# nrf9220_application register map
Vendor: Nordic Semiconductor; Series: nRF92; File version: 1
CPU: CM33 r1p0, little endian, MPU, FPU, 3 interrupt priority bits, 480 interrupts, 4 SAU regions
Registers are 32-bit, read-write, reset 0x0 unless marked. A register's access mark holds for its fields unless they carry their own. Offsets are from the block's base; [hi:lo] are bit positions; lines under a group give offsets from that group; {n}, {i} and the like mark numbered series; 'fields as' and 'values as' point back to an identical list; <NAME> marks a mode.

## GLOBAL_STM_NS — System Trace Macrocell
Base 0xBF042000
0xC04 DMASTARTR wo — Starts a DMA transfer. A write of b1 when the DMA peripheral request interface is idle starts a DMA transfer. A write of b0 has no effect. A write of b1 when the DMA peripheral request interface is active has no effect.
  [0] START — Start a DMA transfer.
    0=NoEffect; 1=Start a DMA transfer
0xC08 DMASTOPR wo — Stops a DMA transfer. A write of b1 stops an active DMA transfer. A write of b0 has no effect. A write of b1 when the DMA peripheral request interface is idle has no effect.
  [0] STOP — Stop a DMA transfer.
    0=NoEffect; 1=Stop a DMA transfer
0xC0C DMASTATR ro — Indicates whether a DMA transfer is in progress.
  [0] STATUS — Status of the DMA peripheral request interface.
    0=Idle (Interface is idle.); 1=Active (Interface is active.)
0xC10 DMACTLR — Controls the DMA transfer request mechanism.
  [3:2] SENS — Determines the sensitivity of the DMA request to the current buffer level in the STM
    0=LT25 (Buffer is <25 percent full.); 1=LT50 (Buffer is <50 percent full.); 2=LT75 (Buffer is <75 percent full.); 3=LT100 (Buffer is <100 percent full.)
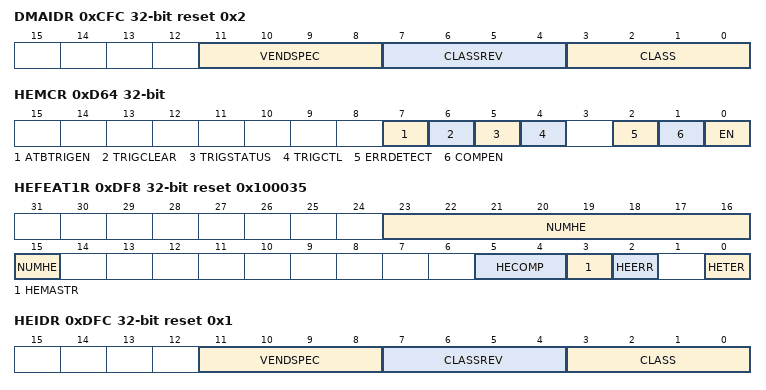
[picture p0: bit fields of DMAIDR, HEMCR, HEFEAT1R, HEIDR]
0xCFC DMAIDR ro reset 0x2 — Indicates the features of the DMA controls in the STM.
  [11:8] VENDSPEC — The VENDSPEC field identifies any vendor specific modifications or mappings
  [7:4] CLASSREV — The CLASSREV field identifies the revision of the programmers model
  [3:0] CLASS — The CLASS field identifies the programmers model
    2=DMA control programmers model
0xD00 HEER — Enables hardware events to generate trace.
  [31:0] HEE — Hardware event enable, with one bit per hardware event. A bit value of b0 disables and b1 enables the corresponding hardware event. Bit 0 applies to the lowest-numbered event. The reset value of each bit is UNKNOWN.
0xD20 HETER — Enables trigger generation on hardware events.
  [31:0] HETE — Bit mask to enable trigger generation from the hardware events, with one bit per hardware event. A bit value of b0 disables and b1 enables trigger generation. The reset value of each bit is UNKNOWN.
0xD64 HEMCR — Controls the primary functions of the hardware event tracing.
  [7] ATBTRIGEN — ATB trigger enable on events being monitored using the HETER. When set, this bit enables the STM to use the ATID value of 0x7D.
    0=Disabled (ATB trigger generation is disabled.); 1=Enabled (ATB trigger generation is enabled.)
  [6] TRIGCLEAR wo — When TRIGCTL indicates single-shot mode, this bit is used to clear TRIGSTATUS. Writing a b1 to this bit when in multi-shot mode is Unpredictable.
    0=NoEffect; 1=Clears TRIGSTATUS if TRIGSTATUS is b1
  [5] TRIGSTATUS ro — When TRIGCTL indicates single-shot mode, this indicates whether the single trigger has occurred. In multi-shot mode this bit is always UNKNOWN.
    0=NotOccurred (Trigger has not occurred.); 1=Occurred (Trigger has occurred.)
  [4] TRIGCTL — Trigger control.
    0=MultiShot (Triggers are multi-shot.); 1=SingleShot (Triggers are single-shot.)
  [2] ERRDETECT — Enable error detection on the hardware event tracing. If an event cannot be traced, this bit enables indication of the lost information.
    0=Disabled (Error detection is disabled.); 1=Enabled (Error detection is enabled.)
  [1] COMPEN — Enable leading zero suppression of hardware event data values in the trace stream.
    0=Disabled (Leading zero suppression is disabled.); 1=Enabled (Leading zero suppression is enabled.)
  [0] EN — Enable hardware event tracing. To enable hardware event tracing, TCSR.EN must also be b1.
    0=Disabled (Hardware event tracing is disabled.); 1=Enabled (Hardware event tracing is enabled.)
0xDF4 HEMASTR ro reset 0x80 — Indicates the STPv2 master number of hardware event trace. This number is the master number presented in STPv2.
  [15:0] MASTER — The STPv2 master number that hardware event traces should be associated with.
0xDF8 HEFEAT1R ro reset 0x100035 — Indicates the features of the STM.
  [23:15] NUMHE — The number of hardware events supported by the STM
  [5:4] HECOMP — Data compression on hardware event tracing support
    0=NotDefinedHere (Data compression support is not defined here. Use the part number of the device to determine if data compression is supported.); 1=NotSupported (No data compression supported.); 2=AlwaysEnabled (Data compression always enabled.); 3=Programmable (Data compression support is programmable. STMHEMCR.COMPEN is implemented.)
  [3] HEMASTR — STMHEMASTR support
    0=ReadOnly (STMHEMASTR is read-only.); 1=ReadWrite (STMHEMASTR is read-write.)
  [2] HEERR — Hardware event error detection support
    0=NotImplemented (The feature is not implemented.); 1=Implemented (The feature is implemented.)
  [0] HETER — STMHETER support
    values as HEERR
0xDFC HEIDR ro reset 0x1 — Indicates the features of hardware event tracing in the STM.
  [11:8] VENDSPEC — The VENDSPEC field identifies any vendor specific modifications or mappings
  [7:4] CLASSREV — The CLASSREV field identifies the revision of the programmers model
  [3:0] CLASS — The CLASS field identifies the programmers model
    1=Hardware Event Control programmers model
0xE00 SPER — Enables the stimulus port registers to generate trace. This register defines one bit per stimulus port. This register is used in conjunction with the SPSCR.
  [31:0] SPE — Stimulus port enable, with one bit per stimulus port. A bit value of b0 disables and b1 enables the corresponding stimulus port. The reset value of each bit is b0.
0xE20 SPTER — Enables trigger generation on writes to enabled stimulus port registers.
  [31:0] SPTE — Bit mask to enable trigger generation from the stimulus port registers, with one bit per stimulus port register. A bit value of b0 disables and b1 enables trigger generation. The reset value of each bit is b0.
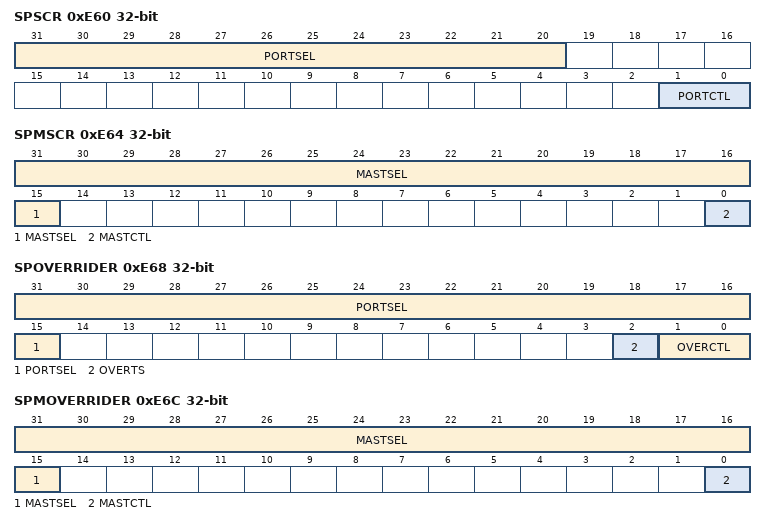
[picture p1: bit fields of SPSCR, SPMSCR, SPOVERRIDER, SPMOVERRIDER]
0xE60 SPSCR — Enables a debugger to program which stimulus ports the SPER and SPTER apply to.
  [31:20] PORTSEL — Port Selection. This field defines which group of 32 stimulus ports the SPTER and SPER apply to. The bottom N bits which are 0 define a mask, a 1 in bit N+1 demarks the mask from the port selection, and the remaining bits select the groups. The effective size of this field is defined by the number of implemented stimulus ports. The reset value is UNKNOWN.
  [1:0] PORTCTL — This defines how the port selection is applied. The reset value is b00.
    0=NotUsed (Port selection not used. SPER and SPTER apply equally to every group of 32 stimulus ports and PORTSEL is ignored.); 1=TriggerEnableOnly (Port selection applies only to the SPTER.); 3=EnableAndTriggerEnable (Port selection applies to both the SPER and SPTER.)
0xE64 SPMSCR — Enables a debugger to program which masters the SPSCR applies to.
  [31:15] MASTSEL — Master Selection. This field defines which master the SPSCR applies to. The bottom N bits which are 0 define a mask, a 1 in bit N+1 demarks the mask from the master selection, and the remaining bits select the master. The effective size of this field is defined by the number of implemented masters. The reset value is UNKNOWN.
  [0] MASTCTL — This bit defines how the master is applied. The reset value is b0.
    0=NotUsed (Master selection not used. The port selection used by the SPSCR applies equally to all masters and MASTSEL is ignored.); 1=Used (Master selection applies to the SPSCR.)
0xE68 SPOVERRIDER — Enables a debugger to override various features of the STM. This register is used in conjunction with SPMOVERRIDER.
  [31:15] PORTSEL — Port selection. This field defines which stimulus ports the override controls apply to. The bottom N bits which are 0 define a mask, a 1 in bit N+1 delimits the mask from the port selection, and the remaining bits select the ports. The effective size of this field is defined by the number of implemented stimulus ports. The reset value is UNKNOWN.
  [2] OVERTS — Timestamping override. This override requests all stimulus port writes that cause trace to be traced with a timestamp where possible. As with normal operation, this does not ensure all packets are generated with timestamps. This field is independent of OVERCTL, PORTSEL and SPMOVERRIDER. The reset value is b0.
    0=Disabled (Override not enabled.); 1=Enabled (Override enabled.)
  [1:0] OVERCTL — This defines how the port selection is applied. The reset value is b00.
    0=Disabled (Override controls disabled.); 1=Guaranteed (Ports selected by PORTSEL always behave as guaranteed transactions.); 2=InvariantTiming (Ports selected by PORTSEL always behave as invariant timing transactions.)
0xE6C SPMOVERRIDER — Enables a debugger to select which masters the SPOVERRIDER applies to.
  [31:15] MASTSEL — Master selection. This field defines which master the override controls apply to. The effective size of this field is defined by the number of implemented masters. The reset value is UNKNOWN.
  [0] MASTCTL — This bit defines how the master selection is applied. The reset value is b0.
    0=NotUsed (Master selection not enabled. SPOVERRIDER applies equally to all masters and MASTSEL is ignored.); 1=Used (Master selection enabled. SPOVERRIDER applies to the masters selected by MASTSEL.)
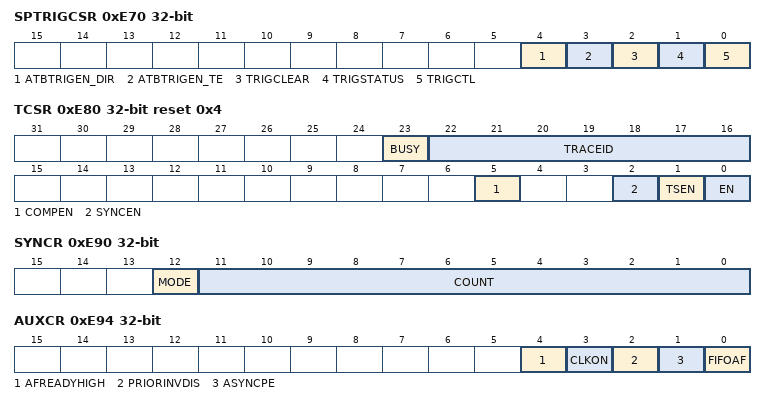
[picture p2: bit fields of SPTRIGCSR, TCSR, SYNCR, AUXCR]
0xE70 SPTRIGCSR — Controls the STM triggers caused by the SPTER.
  [4] ATBTRIGEN_DIR — ATB trigger enable on direct writes to TRIG locations in an extended stimulus port. When set, this bit enables the STM to use the ATID value of 0x7D when software writes to the TRIG locations. The reset value is b0.
    values as HEMCR.ATBTRIGEN
  [3] ATBTRIGEN_TE — ATB trigger enable on writes to stimulus ports being monitored using the SPTER. When set, this bit enables the STM to use the ATID value of 0x7D when software writes to an enabled stimulus port. The reset value is b0.
    values as HEMCR.ATBTRIGEN
  [2] TRIGCLEAR wo — When TRIGCTL indicates single-shot mode, this bit is used to clear TRIGSTATUS. Writing a b1 to this bit when in multi-shot mode is Unpredictable.
    0=NoEffect; 1=Clears TRIGSTATUS if TRIGSTATUS is b1
  [1] TRIGSTATUS ro — When TRIGCTL indicates single-shot mode, this bit indicates whether the single trigger has occurred. In multi-shot mode this bit is always UNK/SBZP.
    values as HEMCR.TRIGSTATUS
  [0] TRIGCTL — Trigger control. The reset value is b0.
    values as HEMCR.TRIGCTL
0xE80 TCSR reset 0x4 — Controls the STM settings.
  [23] BUSY — STM is busy, for example the STM trace FIFO is not empty.
    0=Ready (STM is not busy.); 1=Busy (STM is busy.)
  [22:16] TRACEID — ATB Trace ID. Setting this value to all zeroes might result in Unpredictable tracing.
  [5] COMPEN — Compression Enable for Stimulus Ports.
    0=Disabled (Compression disabled, data transfers are transmitted at the size of the transaction.); 1=Enabled (Compression enabled, data transfers are compressed to save bandwidth.)
  [2] SYNCEN — STMSYNCR is implemented so this value is Read As One.
    0=Disabled (The STM Sync feature is disabled.); 1=Enabled (The STM Sync feature is enabled.)
  [1] TSEN — Enable or disable timestamp bundling.
    0=Disabled (Time stamps are disabled. Requests for timestamp generation are ignored, and stimulus port writes selecting timestamping are treated as if it were not selected.); 1=Enabled (Time stamps are enabled. If stimulus writes select timestamping, a timestamp is output according to STPv2.)
  [0] EN — Global STM enable
    0=Disabled (The STM is disabled.); 1=Enabled (The STM is enabled.)
0xE84 TSSTIMR wo — Forces the next packet caused by a stimulus port write to have a timestamp output.
  [0] FORCETS — Force timestamp stimulus.
    0=Ignored (Writes with this bit b0 are ignored.); 1=Force (Requests the next stimulus port write which causes trace to be upgraded to have a timestamp.)
0xE8C TSFREQR — Indicates the frequency of the timestamp counter. The unit of measurement is increments per second.
  [31:0] FREQ — The timestamp frequency in Hz. A value of zero indicates the timestamp frequency is not known. The reset value is implementation defined.
0xE90 SYNCR — Controls the interval between synchronization packets, in terms of the number of bytes of trace generated. This register only provides a hint of the desired synchronization frequency, because implementations are permitted to be inaccurate. Writing a value of 0x00000000 disables the synchronization counter.
  [12] MODE — Mode control. The reset value is b0.
    0=Linear (COUNT[11:0] defines a value N. Synchronization period is N bytes.); 1=PowerOfTwo (COUNT[11:7] defines a value N. Synchronization period is 2N bytes. N must be in the range 12 to 27 inclusive and other values are Unpredictable.)
  [11:0] COUNT — Counter value for the number of bytes between synchronization packets. Reads return the value of this register. The reset value is implementation defined.
0xE94 AUXCR — Used for implementation defined STM controls.
  [4] AFREADYHIGH — Provides override control for the AFREADY output
    0=Disabled (No override, AFREADY is controlled by the state of STM.); 1=Enabled (Override, AFREADY is driven HIGH.)
  [3] CLKON — Provides override control for architectural clock gate enable.
    0=Disabled (No override, clock gate is controlled by the state of STM.); 1=Enabled (Override, clock is enabled.)
  [2] PRIORINVDIS — Controls arbitration between AXI and HW during flush.
    0=Priority inversion, when AXI flush is finished, HW gets priority until HW flush is done; 1=AxiAlwaysFirst (Priority inversion disabled, AXI always has priority over HW.)
  [1] ASYNCPE — Is ASYNC priority higher than trace?
    0=Lower (ASYNC priority is always lower than trace.); 1=Escalate (ASYNC priority escalates on second synchronization request.)
  [0] FIFOAF — FIFO Auto-flush.
    0=Disabled (Auto-flush is disabled.); 1=Enabled (Auto-flush is enabled. The STM automatically drains all data it has even if the ATB interface is not fully utilized.)
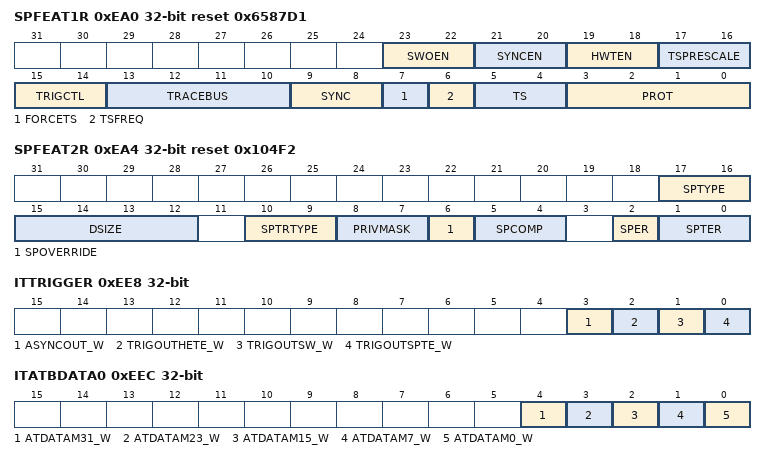
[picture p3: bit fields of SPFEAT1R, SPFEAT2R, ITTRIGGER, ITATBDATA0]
0xEA0 SPFEAT1R ro reset 0x6587D1 — Indicates the features of the STM.
  [23:22] SWOEN — STMTCSR.SWOEN support
    1=NotImplemented (STMTCSR.SWOEN not implemented)
  [21:20] SYNCEN — STMTCSR.SYNCEN support
    2=ReadAsOne (STMTCSR.SYNCEN implemented but always reads as b1)
  [19:18] HWTEN — STMTCSR.HWTEN support
    1=NotImplemented (STMTCSR.HWTEN is not implemented)
  [17:16] TSPRESCALE — Timestamp prescale support
    1=NotImplemented (Timestamp prescale is not implemented.); 2=Implemented (Timestamp prescale is implemented.)
  [15:14] TRIGCTL — Trigger control support.
    2=Multi-shot and single-shot triggers supported. STMSPTRIGCSR implemented.
  [13:10] TRACEBUS — Trace bus support.
    1=AtbPlusTrigger (CoreSight ATB plus ATB trigger support implemented. STMTCSR.TRACEID and STMSPTRIGCSR.ATBTRIGEN implemented.)
  [9:8] SYNC — STMSYNCR support.
    3=ImplementedWithMode (STMSYNCR implemented with MODE control.)
  [7] FORCETS — Timestamp force configuration.
    0=NotImplemented (STMTSSTIMR bit 0 is read-only.); 1=Implemented (STMTSSTIMR bit 0 is read-write.)
  [6] TSFREQ — Timestamp frequency indication configuration.
    0=NotImplemented (STMTSFREQR is read-only.); 1=Implemented (STMTSFREQR is read-write.)
  [5:4] TS — Timestamp support.
    1=Absolute timestamps implemented
  [3:0] PROT — Indicates the implemented STM protocol.
    1=STPV2 (STM implements the STPV2 protocol.)
0xEA4 SPFEAT2R ro reset 0x104F2 — Indicates the features of the STM.
  [17:16] SPTYPE — Stimulus port type support
    1=Only extended stimulus ports are implemented
  [15:12] DSIZE — Fundamental data size.
    0=Bits32 (32-bit data.)
  [10:9] SPTRTYPE — Stimulus port transaction type support.
    2=InvariantAndGuaranteed (Both invariant timing and guaranteed transactions are supported.)
  [8:7] PRIVMASK — STMPRIVMASKR support.
    1=NotImplemented (STMPRIVMASKR is not implemented.)
  [6] SPOVERRIDE — STMSPOVERRIDER and STMSPMOVERRIDER support.
    0=NotImplemented (STMSPOVERRIDER and STMSPMOVERRIDER is not implemented.); 1=Implemented (STMSPOVERRIDER and STMSPMOVERRIDER is implemented.)
  [5:4] SPCOMP — Data compression on stimulus ports support.
    3=Programmable (Data compression support is programmable. STMTCSR.COMPEN is implemented.)
  [2] SPER — STMSPER presence.
    0=Implemented (STMSPER is implemented.); 1=NotImplemented (STMSPER is not implemented.)
  [1:0] SPTER — STMSPTER support.
    2=Implemented (STMSPTER is implemented.)
0xEA8 SPFEAT3R ro reset 0x7F — Indicates the features of the STM.
  [6:0] NUMMAST — The number of stimulus ports masters implemented, minus 1.
    127=Masters128 (128 masters are implemented.)
0xEE8 ITTRIGGER wo — Integration Test for Cross-Trigger Outputs Register.
  [all] fields
    0=Low (Drive logic 0 on output.); 1=High (Drive logic 1 on output.)
  [3] ASYNCOUT_W — Sets the value of the ASYNCOUT output in integration mode.
  [2] TRIGOUTHETE_W — Sets the value of the TRIGOUTHETE output in integration mode.
  [1] TRIGOUTSW_W — Sets the value of the TRIGOUTSW output in integration mode.
  [0] TRIGOUTSPTE_W — Sets the value of the TRIGOUTSPTE output in integration mode.
0xEEC ITATBDATA0 wo — Controls the value of the ATDATAM output in integration mode.
  [all] fields
    values as the fields of ITTRIGGER
  [4] ATDATAM31_W — Sets the value of the ATDATAM[31].
  [3] ATDATAM23_W — Sets the value of the ATDATAM[23].
  [2] ATDATAM15_W — Sets the value of the ATDATAM[15].
  [1] ATDATAM7_W — Sets the value of the ATDATAM[7] output.
  [0] ATDATAM0_W — Sets the value of the ATDATAM[0].
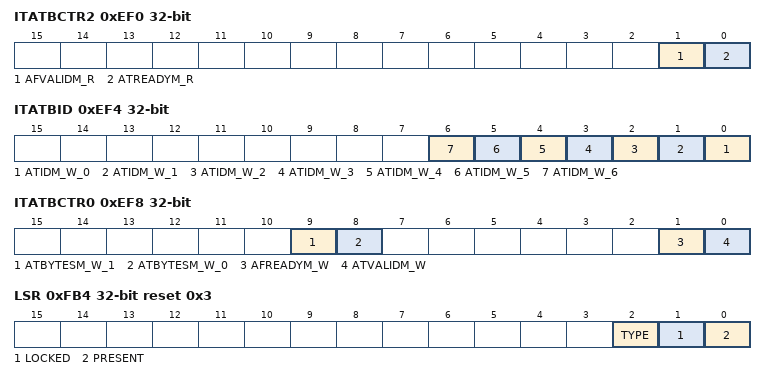
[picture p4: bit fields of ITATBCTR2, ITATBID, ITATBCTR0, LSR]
0xEF0 ITATBCTR2 ro — Returns the value of the ATREADYM and AFVALIDM inputs in integration mode.
  [1] AFVALIDM_R — Reads the value of the AFVALIDM input.
    0=Low (Pin is at logic 0.); 1=High (Pin is at logic 1.)
  [0] ATREADYM_R — Reads the value of the ATREADYM input.
    0=Low (Pin is at logic 0.); 1=High (Pin is at logic 1.)
0xEF4 ITATBID wo — Controls the value of the ATIDM output in integration mode.
  [all] fields
    values as the fields of ITTRIGGER
  [n] ATIDM_W_{n} (n=0..6) — Sets the value of pin {n} of the ATIDM output.
0xEF8 ITATBCTR0 wo — Controls the value of the ATVALIDM, AFREADYM, and ATBYTESM outputs in integration mode.
  [all] fields
    values as the fields of ITTRIGGER
  [9] ATBYTESM_W_1 — Sets the value of pin 1 of the ATBYTESM output.
  [8] ATBYTESM_W_0 — Sets the value of pin 0 of the ATBYTESM output.
  [1] AFREADYM_W — Sets the value of the AFREADYM output.
  [0] ATVALIDM_W — Sets the value of the ATVALIDM output.
0xF00 ITCTRL — Used to enable topology detection. This register enables the component to switch from a functional mode, the default behavior, to integration mode where the inputs and outputs of the component can be directly controlled for integration testing and topology solving.
  [0] INTEGRATIONMODE — Enables the component to switch from functional mode to integration mode and back. If no integration functionality is implemented, this register must read as zero.
    0=Disabled (Integration mode is disabled.); 1=Enabled (Integration mode is Enabled.)
0xFA0 CLAIMSET reset 0xF — On writes this register sets bits of the claim tag. On reads it indicates the number of claim tag bits implemented.
  [3:0] CLAIMSET — On reads, each bit reads as b1 if the claim tag bit is implemented. Four claim tag bits are implemented, so this register reads as 0xF. On writes, a b1 in a bit position causes the corresponding claim tag bit to be set.
0xFA4 CLAIMCLR — On writes this register clears bits of the claim tag. On reads it indicates the current status of the claim tag.
  [3:0] CLAIMCLR — On reads, each bit reads as one if the claim tag bit is set. On writes, a b1 in a bit position causes the corresponding claim tag bit to be cleared. On a reset the claim tags are reset to b0.
0xFB0 LAR wo — This is used to enable write access to device registers.
  [31:0] ACCESS — A write of 0xC5ACCE55 enables further write access to this device. Any other write removes write access.
    0xC5ACCE55=Unlock register interface
0xFB4 LSR ro reset 0x3 — This indicates the status of the lock control mechanism. This lock prevents accidental writes by code under debug. Accesses to the extended stimulus port registers are not affected by the lock mechanism. This register must always be present although there might not be any lock access control mechanism. The lock mechanism, where present and locked, must block write accesses to any control register, except the Lock Access Register. For most components this covers all registers except for the Lock Access Register.
  [2] TYPE — Indicates if the Lock Access Register is implemented as 8-bit or 32-bit.
    0=Bits32 (This component implements a 32-bit Lock Access Register.); 1=Bits8 (This component implements an 8-bit Lock Access Register.)
  [1] LOCKED — Returns the current status of the Lock.
    0=UnLocked (Write access is allowed to this device.); 1=Locked (Write access to the component is blocked. All writes to control registers are ignored. Reads are permitted.)
  [0] PRESENT — Indicates that a lock control mechanism exists for this device.
    0=NotImplemented (No lock control mechanism exists, writes to the Lock Access Register are ignored.); 1=Implemented (Lock control mechanism is present.)
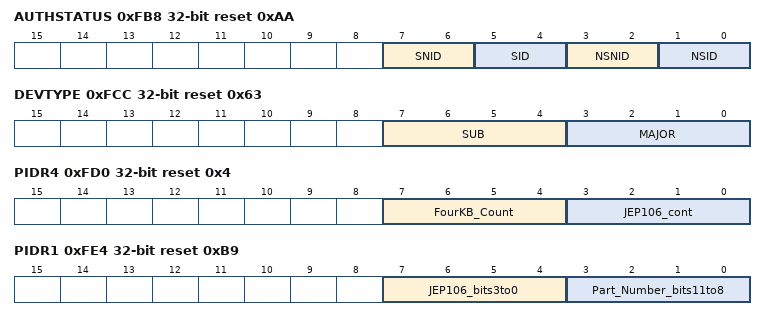
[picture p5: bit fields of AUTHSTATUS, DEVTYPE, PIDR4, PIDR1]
0xFB8 AUTHSTATUS ro reset 0xAA — Indicates the current level of tracing permitted by the system
  [all] fields
    2=Disabled (Functionality disabled.); 3=Enabled (Functionality enabled.)
  [7:6] SNID — Indicates the security level for secure non-invasive debug.
  [5:4] SID — Indicates the security level for secure invasive debug.
  [3:2] NSNID — Indicates the security level for non-secure non-invasive debug.
  [1:0] NSID — Indicates the security level for non-secure invasive debug.
0xFC8 DEVID ro reset 0x10000 — Indicates the capabilities of the STM.
  [16:0] NUMSP — This value indicates the number of stimulus ports implemented.
    0x10000=Max (Maximum 65,536 stimulus ports can be implemented.)
0xFCC DEVTYPE ro reset 0x63 — Provides a debugger with information about the component when the Part Number field is not recognized. The debugger can then report this information.
  [7:4] SUB — The sub-type of the component
    6=StimulusTrace (Peripheral is a stimulus trace source.)
  [3:0] MAJOR — The main type of the component
    3=TraceSource (Peripheral is a trace source.)
0xFD0 PIDR4 ro reset 0x4 — Coresight peripheral identification register. Contains part of the designer identity and the memory footprint indicator.
  [7:4] FourKB_Count — This is a 4-bit value that indicates the total contiguous size of the memory window used by this component in powers of 2 from the standard 4KB. If a component only requires the standard 4KB, this must read as 0x0, 4KB only. For 8KB set to 0x1, for 16KB set to 0x2, for 32KB set to 0x3, and so on.
    0=Size4KB (Indicates that the device only occupies 4KB of memory.)
  [3:0] JEP106_cont — JEDEC continuation code indicating the designer of the component, together with the identity code.
    4=Arm (Indicates that ARM's JEDEC identity code is on the 5th bank.)
0xFE0 PIDR0 ro reset 0x62 — Coresight peripheral identification register. Contains part of the designer specific part number.
  [7:0] Part_Number_bits7to0 — Bits [7:0] of the component part number. This is selected by the designer of the component.
    98=PartNumberLow (Lowest 8 bits of the Part Number, 0x962.)
0xFE4 PIDR1 ro reset 0xB9 — Coresight peripheral identification register. Contains part of the designer specific part number and part of the designer identity.
  [7:4] JEP106_bits3to0 — Bits [3:0] of the JEDEC identity code indicating the designer of the component, together with the continuation code.
    11=JEP106IdentityLow (Lowest 4 bits of the JEP106 Identity Code.)
  [3:0] Part_Number_bits11to8 — Bits [11:8] of the component part number. This is selected by the designer of the component.
    9=PartNumberHigh (Upper 4 bits of the Part Number, 0x962.)
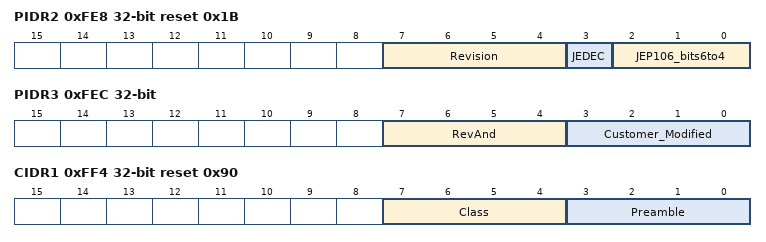
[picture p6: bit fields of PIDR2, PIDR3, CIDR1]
0xFE8 PIDR2 ro reset 0x1B — Coresight peripheral identification register. Contains part of the designer identity and the product revision.
  [7:4] Revision — The Revision field is an incremental value starting at 0x0 for the first design of this component. This only increases by 1 for both major and minor revisions and is used as a look-up to establish the exact major and minor revision.
    1=R0P1 (This device is at r0p1.)
  [3] JEDEC — Always set. Indicates that a JEDEC assigned value is used.
    1=JedecAssigned (The designer ID is specified by JEDEC (http://www.jedec.org).)
  [2:0] JEP106_bits6to4 — Bits [6:4] of the JEDEC identity code indicating the designer of the component, together with the continuation code.
    3=JEP106IdentityHigh (Upper 3 bits of the JEP106 Identity Code.)
0xFEC PIDR3 ro — Coresight peripheral identification register. Contains the RevAnd and Customer Modified fields.
  [7:4] RevAnd — This field indicates minor errata fixes specific to this design, for example metal fixes after implementation. In most cases this field is zero.
    0=NoMetalFixes (Indicates that there have been no metal fixes to this component.)
  [3:0] Customer_Modified — Where the component is reusable IP, this value indicates if the customer has modified the behavior of the component. In most cases this field is zero.
    0=NoModifications (Indicates that there have been no modifications made.)
0xFF0 CIDR0 ro reset 0xD — Coresight component identification register, that indicates that the identification registers are present.
  [7:0] Preamble — Contains bits [24:31] of the component identification.
    13=IdentificationValue
0xFF4 CIDR1 ro reset 0x90 — Coresight component identification register, that indicates that the identification registers are present. This register also indicates the component class.
  [7:4] Class — Class of the component, for example, ROM table or CoreSight component.
    9=CoreSightComponent (Indicates the component is a CoreSight component.)
  [3:0] Preamble — Contains bits [19:16] of the component identification.
    0=IdentificationValue
0xFF8 CIDR2 ro reset 0x5 — Coresight component identification register, that indicates that the identification registers are present.
  [7:0] Preamble — Contains bits [15:8] of the component identification.
    5=IdentificationValue
0xFFC CIDR3 ro reset 0xB1 — Coresight component identification register, that indicates that the identification registers are present.
  [7:0] Preamble — Contains bits [7:0] of the component identification.
    177=IdentificationValue
